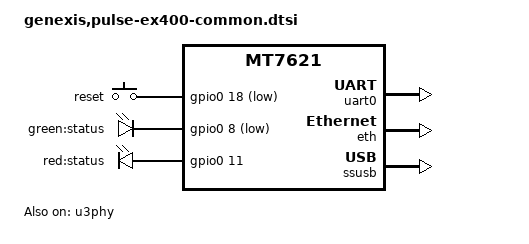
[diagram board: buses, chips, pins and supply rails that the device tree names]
// SPDX-License-Identifier: GPL-2.0
/*
 * Copyright (C) 2024 Mauri Sandberg
 *
 */

#include "mt7621.dtsi"
#include <dt-bindings/gpio/gpio.h>
#include <dt-bindings/input/input.h>

/ {
	aliases {
		ethernet0 = &eth;
		serial0 = &uart0;
	};

	chosen {
		stdout-path = &uart0;
	};

	keys {
		compatible = "gpio-keys";

		reset {
			label = "reset";
			gpios = <&gpio0 18 GPIO_ACTIVE_LOW>;
			linux,code = <KEY_RESTART>;
		};
	};

	leds {
		compatible = "gpio-leds";

		led_status_green: led-0 {
			label = "green:status";
			gpios = <&gpio0 8 GPIO_ACTIVE_LOW>;
			default-state = "off";
		};

		led_status_red: led-1 {
			label = "red:status";
			gpios = <&gpio0 11 GPIO_ACTIVE_HIGH>;
			default-state = "on";
		};
	};

	options {
		u-boot {
			activity-led = <&led_status_green>;
			boot-led = <&led_status_red>;
		};
	};

	reserved-memory {
		#address-cells = <1>;
		#size-cells = <1>;
		ranges;

		ramoops@8d000000 {
			compatible = "ramoops";
			reg = <0x8d000000 0x00010000>;
			record-size = <0x1000>;
		};
	};
};

&pinctrl {
	state_default: pin_state {
		nand {
			groups = "spi", "sdxc";
			function = "nand";
		};

		gpios {
			groups = "i2c", "uart3", "pcie reset";
			function = "gpio";
		};

		wdt {
			groups = "wdt";
			function = "wdt rst";
		};

		jtag {
			groups = "jtag";
			function = "jtag";
		};
	};
};

&uart0 {
	status = "okay";
};

&gpio {
	status = "okay";
};

&eth {
	status = "okay";
};

&ssusb {
	status = "okay";
};

&u3phy {
	status = "okay";
};
